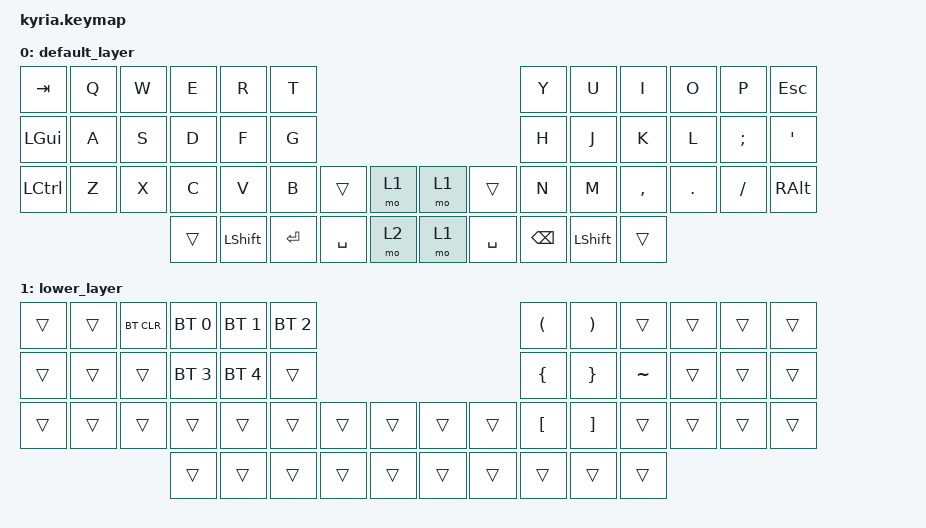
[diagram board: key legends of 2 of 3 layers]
#include <behaviors.dtsi>
#include <dt-bindings/zmk/bt.h>
#include <dt-bindings/zmk/keys.h>

/ {
    keymap {
        compatible = "zmk,keymap";

        default_layer {
            bindings = <
    &kp TAB   &kp Q &kp W &kp E  &kp R     &kp T                                           &kp Y    &kp U     &kp I     &kp O   &kp P    &kp ESC
    &kp LGUI  &kp A &kp S &kp D  &kp F     &kp G                                           &kp H    &kp J     &kp K     &kp L   &kp SEMI &kp SQT
    &kp LCTRL &kp Z &kp X &kp C  &kp V     &kp B   &trans     &mo 1        &mo 1 &trans    &kp N    &kp M     &kp COMMA &kp DOT &kp FSLH &kp RALT
                          &trans &kp LSHFT &kp RET &kp SPACE  &mo 2        &mo 1 &kp SPACE &kp BSPC &kp LSHFT &trans
            >;
        };
        lower_layer {
            bindings = <
    &trans &trans &bt BT_CLR &bt BT_SEL 0 &bt BT_SEL 1 &bt BT_SEL 2                                    &kp LPAR &kp RPAR &trans    &trans &trans &trans
    &trans &trans &trans     &bt BT_SEL 3 &bt BT_SEL 4 &trans                                          &kp LBRC &kp RBRC &kp TILDE &trans &trans &trans
    &trans &trans &trans     &trans       &trans       &trans       &trans &trans        &trans &trans &kp LBKT &kp RBKT &trans    &trans &trans &trans
                             &trans       &trans       &trans       &trans &trans        &trans &trans &trans &trans &trans
            >;
        };
        raise_layer {
          bindings = <
    &trans &kp N1    &kp N2   &kp N3    &kp N4    &kp N5                                       &kp N6   &kp N7   &kp N8   &kp N9    &kp N0    &trans
    &trans &kp CARET &kp AMPS &kp STAR  &kp MINUS &kp UNDER                                    &kp LEFT &kp DOWN &kp UP   &kp RIGHT &kp EXCL  &trans
    &trans &kp EQUAL &kp PLUS &kp GRAVE &kp BSLH  &kp PIPE  &trans &trans        &trans &trans &kp DLLR &kp AT   &kp HASH &kp DLLR  &kp PRCNT &trans
                              &trans    &trans    &trans    &trans &trans        &trans &trans &trans   &trans   &trans &trans
          >;
        };
    };
};
